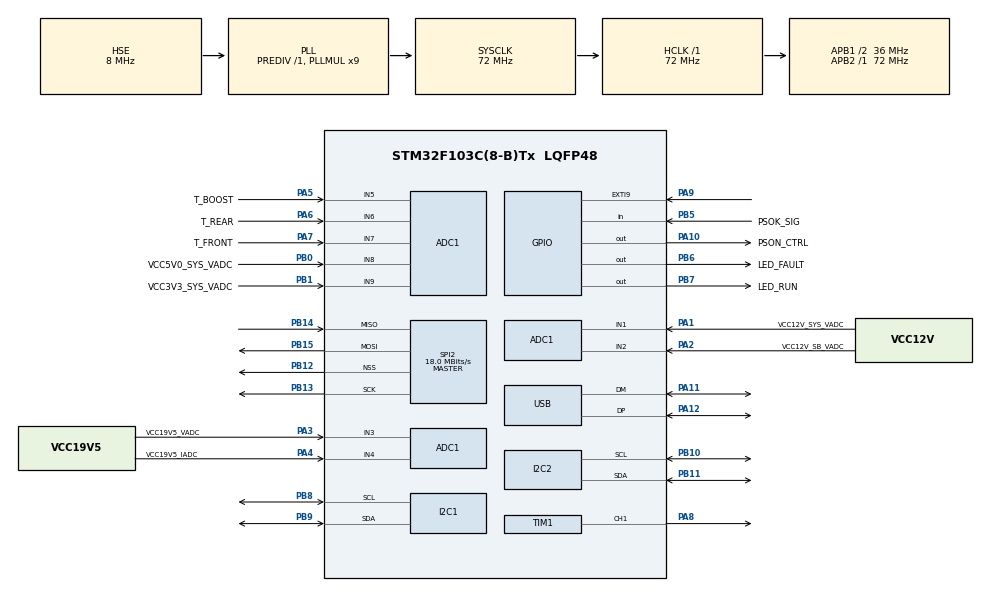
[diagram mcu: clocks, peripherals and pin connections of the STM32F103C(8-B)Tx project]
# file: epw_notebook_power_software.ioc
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ADC1.Channel-1\#ChannelRegularConversion=ADC_CHANNEL_1
ADC1.Channel-12\#ChannelRegularConversion=ADC_CHANNEL_2
ADC1.Channel-13\#ChannelRegularConversion=ADC_CHANNEL_3
ADC1.Channel-14\#ChannelRegularConversion=ADC_CHANNEL_4
ADC1.Channel-15\#ChannelRegularConversion=ADC_CHANNEL_5
ADC1.Channel-16\#ChannelRegularConversion=ADC_CHANNEL_6
ADC1.Channel-17\#ChannelRegularConversion=ADC_CHANNEL_7
ADC1.Channel-18\#ChannelRegularConversion=ADC_CHANNEL_8
ADC1.Channel-19\#ChannelRegularConversion=ADC_CHANNEL_9
ADC1.Channel-20\#ChannelRegularConversion=ADC_CHANNEL_TEMPSENSOR
ADC1.Channel-21\#ChannelRegularConversion=ADC_CHANNEL_VREFINT
ADC1.ContinuousConvMode=ENABLE
ADC1.NbrOfConversion=11
ADC1.NbrOfConversionFlag=1
ADC1.Rank-1\#ChannelRegularConversion=1
ADC1.Rank-12\#ChannelRegularConversion=2
ADC1.Rank-13\#ChannelRegularConversion=3
ADC1.Rank-14\#ChannelRegularConversion=4
ADC1.Rank-15\#ChannelRegularConversion=5
ADC1.Rank-16\#ChannelRegularConversion=6
ADC1.Rank-17\#ChannelRegularConversion=7
ADC1.Rank-18\#ChannelRegularConversion=8
ADC1.Rank-19\#ChannelRegularConversion=9
ADC1.Rank-20\#ChannelRegularConversion=10
ADC1.Rank-21\#ChannelRegularConversion=11
ADC1.SamplingTime-1\#ChannelRegularConversion=ADC_SAMPLETIME_1CYCLE_5
ADC1.SamplingTime-12\#ChannelRegularConversion=ADC_SAMPLETIME_1CYCLE_5
ADC1.SamplingTime-13\#ChannelRegularConversion=ADC_SAMPLETIME_1CYCLE_5
ADC1.SamplingTime-14\#ChannelRegularConversion=ADC_SAMPLETIME_1CYCLE_5
ADC1.SamplingTime-15\#ChannelRegularConversion=ADC_SAMPLETIME_1CYCLE_5
ADC1.SamplingTime-16\#ChannelRegularConversion=ADC_SAMPLETIME_1CYCLE_5
ADC1.SamplingTime-17\#ChannelRegularConversion=ADC_SAMPLETIME_1CYCLE_5
ADC1.SamplingTime-18\#ChannelRegularConversion=ADC_SAMPLETIME_1CYCLE_5
ADC1.SamplingTime-19\#ChannelRegularConversion=ADC_SAMPLETIME_1CYCLE_5
ADC1.SamplingTime-20\#ChannelRegularConversion=ADC_SAMPLETIME_1CYCLE_5
ADC1.SamplingTime-21\#ChannelRegularConversion=ADC_SAMPLETIME_1CYCLE_5
ADC1.master=1
Dma.ADC1.0.Direction=DMA_PERIPH_TO_MEMORY
Dma.ADC1.0.Instance=DMA1_Channel1
Dma.ADC1.0.MemDataAlignment=DMA_MDATAALIGN_HALFWORD
Dma.ADC1.0.MemInc=DMA_MINC_ENABLE
Dma.ADC1.0.Mode=DMA_CIRCULAR
Dma.ADC1.0.PeriphDataAlignment=DMA_PDATAALIGN_HALFWORD
Dma.ADC1.0.PeriphInc=DMA_PINC_DISABLE
Dma.ADC1.0.Priority=DMA_PRIORITY_LOW
Dma.Request0=ADC1
I2C2.I2C_Mode=I2C_Fast
I2C2.NoStretchMode=I2C_NOSTRETCH_DISABLE
I2C2.OwnAddress=0
Mcu.Family=STM32F1
Mcu.Name=STM32F103C(8-B)Tx
Mcu.Package=LQFP48
NVIC.DMA1_Channel1_IRQn=true\:0\:0\:false\:false\:true\:false\:true\:true
NVIC.EXTI9_5_IRQn=true\:0\:0\:false\:false\:true\:true\:true\:true
NVIC.PriorityGroup=NVIC_PRIORITYGROUP_4
NVIC.TIM2_IRQn=true\:0\:0\:false\:false\:true\:true\:true\:true
NVIC.USB_LP_CAN1_RX0_IRQn=true\:0\:0\:false\:false\:true\:false\:true\:true
PA1.GPIO_Label=VCC12V_SYS_VADC
PA1.Signal=ADCx_IN1
PA10.GPIO_Label=PSON_CTRL
PA10.GPIO_PuPd=GPIO_PULLDOWN
PA10.PinState=GPIO_PIN_RESET
PA10.Signal=GPIO_Output
PA11.Mode=Device
PA11.Signal=USB_DM
PA12.Mode=Device
PA12.Signal=USB_DP
PA13.Mode=Serial_Wire
PA13.Signal=SYS_JTMS-SWDIO
PA14.Mode=Serial_Wire
PA14.Signal=SYS_JTCK-SWCLK
PA2.GPIO_Label=VCC12V_SB_VADC
PA2.Signal=ADCx_IN2
PA3.GPIO_Label=VCC19V5_VADC
PA3.Signal=ADCx_IN3
PA4.GPIO_Label=VCC19V5_IADC
PA4.Signal=ADCx_IN4
PA5.GPIO_Label=T_BOOST
PA5.Signal=ADCx_IN5
PA6.GPIO_Label=T_REAR
PA6.Signal=ADCx_IN6
PA7.GPIO_Label=T_FRONT
PA7.Signal=ADCx_IN7
PA8.GPIO_ModeDefaultPP=GPIO_MODE_AF_PP
PA8.GPIO_Speed=GPIO_SPEED_FREQ_HIGH
PA8.Signal=S_TIM1_CH1
PA9.GPIO_ModeDefaultEXTI=GPIO_MODE_IT_RISING_FALLING
PA9.GPIO_PuPd=GPIO_PULLUP
PA9.Signal=GPXTI9
PB0.GPIO_Label=VCC5V0_SYS_VADC
PB0.Signal=ADCx_IN8
PB1.GPIO_Label=VCC3V3_SYS_VADC
PB1.Signal=ADCx_IN9
PB10.Mode=I2C
PB10.Signal=I2C2_SCL
PB11.Mode=I2C
PB11.Signal=I2C2_SDA
PB12.Mode=NSS_Signal_Hard_Output
PB12.Signal=SPI2_NSS
PB13.Mode=Full_Duplex_Master
PB13.Signal=SPI2_SCK
PB14.Mode=Full_Duplex_Master
PB14.Signal=SPI2_MISO
PB15.Mode=Full_Duplex_Master
PB15.Signal=SPI2_MOSI
PB5.GPIO_Label=PSOK_SIG
PB5.Signal=GPIO_Input
PB6.GPIO_Label=LED_FAULT
PB6.Signal=GPIO_Output
PB7.GPIO_Label=LED_RUN
PB7.PinState=GPIO_PIN_SET
PB7.Signal=GPIO_Output
PB8.Mode=I2C
PB8.Signal=I2C1_SCL
PB9.Mode=I2C
PB9.Signal=I2C1_SDA
PC14-OSC32_IN.Mode=LSE-External-Oscillator
PC14-OSC32_IN.Signal=RCC_OSC32_IN
PC15-OSC32_OUT.Mode=LSE-External-Oscillator
PC15-OSC32_OUT.Signal=RCC_OSC32_OUT
PD0-OSC_IN.Mode=HSE-External-Oscillator
PD0-OSC_IN.Signal=RCC_OSC_IN
PD1-OSC_OUT.Mode=HSE-External-Oscillator
PD1-OSC_OUT.Signal=RCC_OSC_OUT
ProjectManager.HeapSize=0x200
ProjectManager.StackSize=0x400
ProjectManager.TargetToolchain=STM32CubeIDE
RCC.ADCPresc=RCC_ADCPCLK2_DIV6
RCC.AHBFreq_Value=72000000
RCC.APB1CLKDivider=RCC_HCLK_DIV2
RCC.APB1Freq_Value=36000000
RCC.APB1TimFreq_Value=72000000
RCC.APB2Freq_Value=72000000
RCC.APB2TimFreq_Value=72000000
RCC.HCLKFreq_Value=72000000
RCC.PLLMUL=RCC_PLL_MUL9
RCC.SYSCLKFreq_VALUE=72000000
RCC.SYSCLKSource=RCC_SYSCLKSOURCE_PLLCLK
RCC.USBFreq_Value=48000000
RCC.USBPrescaler=RCC_USBCLKSOURCE_PLL_DIV1_5
SH.ADCx_IN1.0=ADC1_IN1,IN1
SH.ADCx_IN2.0=ADC1_IN2,IN2
SH.ADCx_IN3.0=ADC1_IN3,IN3
SH.ADCx_IN4.0=ADC1_IN4,IN4
SH.ADCx_IN5.0=ADC1_IN5,IN5
SH.ADCx_IN6.0=ADC1_IN6,IN6
SH.ADCx_IN7.0=ADC1_IN7,IN7
SH.ADCx_IN8.0=ADC1_IN8,IN8
SH.ADCx_IN9.0=ADC1_IN9,IN9
SH.S_TIM1_CH1.0=TIM1_CH1,PWM Generation1 CH1
SPI2.BaudRatePrescaler=SPI_BAUDRATEPRESCALER_2
SPI2.CalculateBaudRate=18.0 MBits/s
SPI2.Direction=SPI_DIRECTION_2LINES
SPI2.Mode=SPI_MODE_MASTER
SPI2.VirtualNSS=VM_NSSHARD
SPI2.VirtualType=VM_MASTER
TIM1.Channel-PWM\ Generation1\ CH1=TIM_CHANNEL_1
TIM1.OCMode_PWM-PWM\ Generation1\ CH1=TIM_OCMODE_PWM1
TIM1.Period=1439
TIM1.Prescaler=1
TIM2.AutoReloadPreload=TIM_AUTORELOAD_PRELOAD_DISABLE
TIM2.Period=10000-1
TIM2.Prescaler=7200-1
USB.low_power_enable=DISABLE
USB.lpm_enable=DISABLE
USB_DEVICE.CLASS_NAME_FS=CDC
USB_DEVICE.VirtualMode=Cdc
USB_DEVICE.VirtualModeFS=Cdc_FS
VP_ADC1_TempSens_Input.Mode=IN-TempSens
VP_ADC1_Vref_Input.Mode=IN-Vrefint
VP_IWDG_VS_IWDG.Mode=IWDG_Activate
VP_TIM1_VS_ClockSourceINT.Mode=Internal
VP_TIM2_VS_ClockSourceINT.Mode=Internal
VP_USB_DEVICE_VS_USB_DEVICE_CDC_FS.Mode=CDC_FS
board=custom

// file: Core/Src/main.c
/* USER CODE BEGIN Header */
/**
  ******************************************************************************
  * @file           : main.c
  * @brief          : Main program body
  ******************************************************************************
  * @attention
  *
  * Copyright (c) 2025 STMicroelectronics.
  * All rights reserved.
  *
  * This software is licensed under terms that can be found in the LICENSE file
  * in the root directory of this software component.
  * If no LICENSE file comes with this software, it is provided AS-IS.
  *
  ******************************************************************************
  */
/* USER CODE END Header */
#include "main.h"
#include "usb_device.h"

/* USER CODE BEGIN PD */
#define OLED_ADDRESS 0x78
#define OLED_DATA_ADDRESS 0x40
#define OLED_CMD_ADDRESS 0x00

#define PMBUS_EEPROM_ADDRESS 0xA0
#define PMBUS_MCU_ADDRESS 0xB0
/* USER CODE END PD */

ADC_HandleTypeDef hadc1;
DMA_HandleTypeDef hdma_adc1;

I2C_HandleTypeDef hi2c1;
I2C_HandleTypeDef hi2c2;

IWDG_HandleTypeDef hiwdg;

SPI_HandleTypeDef hspi2;

TIM_HandleTypeDef htim1;
TIM_HandleTypeDef htim2;

/* USER CODE BEGIN PV */
//8*6 ASCII字符集点阵
const unsigned char F6x8[][6] =
{
	0x00, 0x00, 0x00, 0x00, 0x00, 0x00,// sp
	0x00, 0x00, 0x00, 0x2f, 0x00, 0x00,// !
	0x00, 0x00, 0x07, 0x00, 0x07, 0x00,// "
	0x00, 0x14, 0x7f, 0x14, 0x7f, 0x14,// #
	0x00, 0x24, 0x2a, 0x7f, 0x2a, 0x12,// $
	0x00, 0x62, 0x64, 0x08, 0x13, 0x23,// %
	0x00, 0x36, 0x49, 0x55, 0x22, 0x50,// &
	0x00, 0x00, 0x05, 0x03, 0x00, 0x00,// '
	0x00, 0x00, 0x1c, 0x22, 0x41, 0x00,// (
	0x00, 0x00, 0x41, 0x22, 0x1c, 0x00,// )
	0x00, 0x14, 0x08, 0x3E, 0x08, 0x14,// *
	0x00, 0x08, 0x08, 0x3E, 0x08, 0x08,// +
	0x00, 0x00, 0x00, 0xA0, 0x60, 0x00,// ,
	0x00, 0x08, 0x08, 0x08, 0x08, 0x08,// -
	0x00, 0x00, 0x60, 0x60, 0x00, 0x00,// .
	0x00, 0x20, 0x10, 0x08, 0x04, 0x02,// /
	0x00, 0x3E, 0x51, 0x49, 0x45, 0x3E,// 0
	0x00, 0x00, 0x42, 0x7F, 0x40, 0x00,// 1
	0x00, 0x42, 0x61, 0x51, 0x49, 0x46,// 2
	0x00, 0x21, 0x41, 0x45, 0x4B, 0x31,// 3
	0x00, 0x18, 0x14, 0x12, 0x7F, 0x10,// 4
	0x00, 0x27, 0x45, 0x45, 0x45, 0x39,// 5
	0x00, 0x3C, 0x4A, 0x49, 0x49, 0x30,// 6
	0x00, 0x01, 0x71, 0x09, 0x05, 0x03,// 7
	0x00, 0x36, 0x49, 0x49, 0x49, 0x36,// 8
	0x00, 0x06, 0x49, 0x49, 0x29, 0x1E,// 9
	0x00, 0x00, 0x36, 0x36, 0x00, 0x00,// :
	0x00, 0x00, 0x56, 0x36, 0x00, 0x00,// ;
	0x00, 0x08, 0x14, 0x22, 0x41, 0x00,// <
	0x00, 0x14, 0x14, 0x14, 0x14, 0x14,// =
	0x00, 0x00, 0x41, 0x22, 0x14, 0x08,// >
	0x00, 0x02, 0x01, 0x51, 0x09, 0x06,// ?
	0x00, 0x32, 0x49, 0x59, 0x51, 0x3E,// @
	0x00, 0x7C, 0x12, 0x11, 0x12, 0x7C,// A
	0x00, 0x7F, 0x49, 0x49, 0x49, 0x36,// B
	0x00, 0x3E, 0x41, 0x41, 0x41, 0x22,// C
	0x00, 0x7F, 0x41, 0x41, 0x22, 0x1C,// D
	0x00, 0x7F, 0x49, 0x49, 0x49, 0x41,// E
	0x00, 0x7F, 0x09, 0x09, 0x09, 0x01,// F
	0x00, 0x3E, 0x41, 0x49, 0x49, 0x7A,// G
	0x00, 0x7F, 0x08, 0x08, 0x08, 0x7F,// H
	0x00, 0x00, 0x41, 0x7F, 0x41, 0x00,// I
	0x00, 0x20, 0x40, 0x41, 0x3F, 0x01,// J
	0x00, 0x7F, 0x08, 0x14, 0x22, 0x41,// K
	0x00, 0x7F, 0x40, 0x40, 0x40, 0x40,// L
	0x00, 0x7F, 0x02, 0x0C, 0x02, 0x7F,// M
	0x00, 0x7F, 0x04, 0x08, 0x10, 0x7F,// N
	0x00, 0x3E, 0x41, 0x41, 0x41, 0x3E,// O
	0x00, 0x7F, 0x09, 0x09, 0x09, 0x06,// P
	0x00, 0x3E, 0x41, 0x51, 0x21, 0x5E,// Q
	0x00, 0x7F, 0x09, 0x19, 0x29, 0x46,// R
	0x00, 0x46, 0x49, 0x49, 0x49, 0x31,// S
	0x00, 0x01, 0x01, 0x7F, 0x01, 0x01,// T
	0x00, 0x3F, 0x40, 0x40, 0x40, 0x3F,// U
	0x00, 0x1F, 0x20, 0x40, 0x20, 0x1F,// V
	0x00, 0x3F, 0x40, 0x38, 0x40, 0x3F,// W
	0x00, 0x63, 0x14, 0x08, 0x14, 0x63,// X
	0x00, 0x07, 0x08, 0x70, 0x08, 0x07,// Y
	0x00, 0x61, 0x51, 0x49, 0x45, 0x43,// Z
	0x00, 0x00, 0x7F, 0x41, 0x41, 0x00,// [
	0x00, 0x55, 0x2A, 0x55, 0x2A, 0x55,// 55
	0x00, 0x00, 0x41, 0x41, 0x7F, 0x00,// ]
	0x00, 0x04, 0x02, 0x01, 0x02, 0x04,// ^
	0x00, 0x40, 0x40, 0x40, 0x40, 0x40,// _
	0x00, 0x00, 0x01, 0x02, 0x04, 0x00,// '
	0x00, 0x20, 0x54, 0x54, 0x54, 0x78,// a
	0x00, 0x7F, 0x48, 0x44, 0x44, 0x38,// b
	0x00, 0x38, 0x44, 0x44, 0x44, 0x20,// c
	0x00, 0x38, 0x44, 0x44, 0x48, 0x7F,// d
	0x00, 0x38, 0x54, 0x54, 0x54, 0x18,// e
	0x00, 0x08, 0x7E, 0x09, 0x01, 0x02,// f
	0x00, 0x18, 0xA4, 0xA4, 0xA4, 0x7C,// g
	0x00, 0x7F, 0x08, 0x04, 0x04, 0x78,// h
	0x00, 0x00, 0x44, 0x7D, 0x40, 0x00,// i
	0x00, 0x40, 0x80, 0x84, 0x7D, 0x00,// j
	0x00, 0x7F, 0x10, 0x28, 0x44, 0x00,// k
	0x00, 0x00, 0x41, 0x7F, 0x40, 0x00,// l
	0x00, 0x7C, 0x04, 0x18, 0x04, 0x78,// m
	0x00, 0x7C, 0x08, 0x04, 0x04, 0x78,// n
	0x00, 0x38, 0x44, 0x44, 0x44, 0x38,// o
	0x00, 0xFC, 0x24, 0x24, 0x24, 0x18,// p
	0x00, 0x18, 0x24, 0x24, 0x18, 0xFC,// q
	0x00, 0x7C, 0x08, 0x04, 0x04, 0x08,// r
	0x00, 0x48, 0x54, 0x54, 0x54, 0x20,// s
	0x00, 0x04, 0x3F, 0x44, 0x40, 0x20,// t
	0x00, 0x3C, 0x40, 0x40, 0x20, 0x7C,// u
	0x00, 0x1C, 0x20, 0x40, 0x20, 0x1C,// v
	0x00, 0x3C, 0x40, 0x30, 0x40, 0x3C,// w
	0x00, 0x44, 0x28, 0x10, 0x28, 0x44,// x
	0x00, 0x1C, 0xA0, 0xA0, 0xA0, 0x7C,// y
	0x00, 0x44, 0x64, 0x54, 0x4C, 0x44,// z
	0x14, 0x14, 0x14, 0x14, 0x14, 0x14,// horiz lines
};

//16*8 ASCII字符集点阵
const unsigned char F8X16[]=
{
 0x00,0x00,0x00,0x00,0x00,0x00,0x00,0x00,0x00,0x00,0x00,0x00,0x00,0x00,0x00,0x00,//sp /0
 0x00,0x00,0x00,0xF8,0x00,0x00,0x00,0x00,0x00,0x00,0x00,0x33,0x30,0x00,0x00,0x00,//!  /1
 0x00,0x10,0x0C,0x06,0x10,0x0C,0x06,0x00,0x00,0x00,0x00,0x00,0x00,0x00,0x00,0x00,//"  /2
 0x40,0xC0,0x78,0x40,0xC0,0x78,0x40,0x00,0x04,0x3F,0x04,0x04,0x3F,0x04,0x04,0x00,//#  /3
 0x00,0x70,0x88,0xFC,0x08,0x30,0x00,0x00,0x00,0x18,0x20,0xFF,0x21,0x1E,0x00,0x00,//$  /4
 0xF0,0x08,0xF0,0x00,0xE0,0x18,0x00,0x00,0x00,0x21,0x1C,0x03,0x1E,0x21,0x1E,0x00,//%  /5
 0x00,0xF0,0x08,0x88,0x70,0x00,0x00,0x00,0x1E,0x21,0x23,0x24,0x19,0x27,0x21,0x10,//&  /6
 0x10,0x16,0x0E,0x00,0x00,0x00,0x00,0x00,0x00,0x00,0x00,0x00,0x00,0x00,0x00,0x00,//'  /7
 0x00,0x00,0x00,0xE0,0x18,0x04,0x02,0x00,0x00,0x00,0x00,0x07,0x18,0x20,0x40,0x00,//(  /8
 0x00,0x02,0x04,0x18,0xE0,0x00,0x00,0x00,0x00,0x40,0x20,0x18,0x07,0x00,0x00,0x00,//)  /9
 0x40,0x40,0x80,0xF0,0x80,0x40,0x40,0x00,0x02,0x02,0x01,0x0F,0x01,0x02,0x02,0x00,//*  /10
 0x00,0x00,0x00,0xF0,0x00,0x00,0x00,0x00,0x01,0x01,0x01,0x1F,0x01,0x01,0x01,0x00,//+  /11
 0x00,0x00,0x00,0x00,0x00,0x00,0x00,0x00,0x80,0xB0,0x70,0x00,0x00,0x00,0x00,0x00,//,  /12
 0x00,0x00,0x00,0x00,0x00,0x00,0x00,0x00,0x00,0x01,0x01,0x01,0x01,0x01,0x01,0x01,//-  /13
 0x00,0x00,0x00,0x00,0x00,0x00,0x00,0x00,0x00,0x30,0x30,0x00,0x00,0x00,0x00,0x00,//.  /14
 0x00,0x00,0x00,0x00,0x80,0x60,0x18,0x04,0x00,0x60,0x18,0x06,0x01,0x00,0x00,0x00,///  /15
 0x00,0xE0,0x10,0x08,0x08,0x10,0xE0,0x00,0x00,0x0F,0x10,0x20,0x20,0x10,0x0F,0x00,//0  /16
 0x00,0x10,0x10,0xF8,0x00,0x00,0x00,0x00,0x00,0x20,0x20,0x3F,0x20,0x20,0x00,0x00,//1  /17
 0x00,0x70,0x08,0x08,0x08,0x88,0x70,0x00,0x00,0x30,0x28,0x24,0x22,0x21,0x30,0x00,//2  /18
 0x00,0x30,0x08,0x88,0x88,0x48,0x30,0x00,0x00,0x18,0x20,0x20,0x20,0x11,0x0E,0x00,//3  /19
 0x00,0x00,0xC0,0x20,0x10,0xF8,0x00,0x00,0x00,0x07,0x04,0x24,0x24,0x3F,0x24,0x00,//4  /20
 0x00,0xF8,0x08,0x88,0x88,0x08,0x08,0x00,0x00,0x19,0x21,0x20,0x20,0x11,0x0E,0x00,//5  /21
 0x00,0xE0,0x10,0x88,0x88,0x18,0x00,0x00,0x00,0x0F,0x11,0x20,0x20,0x11,0x0E,0x00,//6  /22
 0x00,0x38,0x08,0x08,0xC8,0x38,0x08,0x00,0x00,0x00,0x00,0x3F,0x00,0x00,0x00,0x00,//7  /23
 0x00,0x70,0x88,0x08,0x08,0x88,0x70,0x00,0x00,0x1C,0x22,0x21,0x21,0x22,0x1C,0x00,//8  /24
 0x00,0xE0,0x10,0x08,0x08,0x10,0xE0,0x00,0x00,0x00,0x31,0x22,0x22,0x11,0x0F,0x00,//9  /25
 0x00,0x00,0x00,0xC0,0xC0,0x00,0x00,0x00,0x00,0x00,0x00,0x30,0x30,0x00,0x00,0x00,//:  /26
 0x00,0x00,0x00,0x80,0x00,0x00,0x00,0x00,0x00,0x00,0x80,0x60,0x00,0x00,0x00,0x00,//;  /27
 0x00,0x00,0x80,0x40,0x20,0x10,0x08,0x00,0x00,0x01,0x02,0x04,0x08,0x10,0x20,0x00,//<  /28
 0x40,0x40,0x40,0x40,0x40,0x40,0x40,0x00,0x04,0x04,0x04,0x04,0x04,0x04,0x04,0x00,//=  /29
 0x00,0x08,0x10,0x20,0x40,0x80,0x00,0x00,0x00,0x20,0x10,0x08,0x04,0x02,0x01,0x00,//>  /30
 0x00,0x70,0x48,0x08,0x08,0x08,0xF0,0x00,0x00,0x00,0x00,0x30,0x36,0x01,0x00,0x00,//?  /31
 0xC0,0x30,0xC8,0x28,0xE8,0x10,0xE0,0x00,0x07,0x18,0x27,0x24,0x23,0x14,0x0B,0x00,//@  /32
 0x00,0x00,0xC0,0x38,0xE0,0x00,0x00,0x00,0x20,0x3C,0x23,0x02,0x02,0x27,0x38,0x20,//A  /33
 0x08,0xF8,0x88,0x88,0x88,0x70,0x00,0x00,0x20,0x3F,0x20,0x20,0x20,0x11,0x0E,0x00,//B  /34
 0xC0,0x30,0x08,0x08,0x08,0x08,0x38,0x00,0x07,0x18,0x20,0x20,0x20,0x10,0x08,0x00,//C  /35
 0x08,0xF8,0x08,0x08,0x08,0x10,0xE0,0x00,0x20,0x3F,0x20,0x20,0x20,0x10,0x0F,0x00,//D  /36
 0x08,0xF8,0x88,0x88,0xE8,0x08,0x10,0x00,0x20,0x3F,0x20,0x20,0x23,0x20,0x18,0x00,//E  /37
 0x08,0xF8,0x88,0x88,0xE8,0x08,0x10,0x00,0x20,0x3F,0x20,0x00,0x03,0x00,0x00,0x00,//F  /38
 0xC0,0x30,0x08,0x08,0x08,0x38,0x00,0x00,0x07,0x18,0x20,0x20,0x22,0x1E,0x02,0x00,//G  /39
 0x08,0xF8,0x08,0x00,0x00,0x08,0xF8,0x08,0x20,0x3F,0x21,0x01,0x01,0x21,0x3F,0x20,//H  /40
 0x00,0x08,0x08,0xF8,0x08,0x08,0x00,0x00,0x00,0x20,0x20,0x3F,0x20,0x20,0x00,0x00,//I  /41
 0x00,0x00,0x08,0x08,0xF8,0x08,0x08,0x00,0xC0,0x80,0x80,0x80,0x7F,0x00,0x00,0x00,//J  /42
 0x08,0xF8,0x88,0xC0,0x28,0x18,0x08,0x00,0x20,0x3F,0x20,0x01,0x26,0x38,0x20,0x00,//K  /43
 0x08,0xF8,0x08,0x00,0x00,0x00,0x00,0x00,0x20,0x3F,0x20,0x20,0x20,0x20,0x30,0x00,//L  /44
 0x08,0xF8,0xF8,0x00,0xF8,0xF8,0x08,0x00,0x20,0x3F,0x00,0x3F,0x00,0x3F,0x20,0x00,//M  /45
 0x08,0xF8,0x30,0xC0,0x00,0x08,0xF8,0x08,0x20,0x3F,0x20,0x00,0x07,0x18,0x3F,0x00,//N  /46
 0xE0,0x10,0x08,0x08,0x08,0x10,0xE0,0x00,0x0F,0x10,0x20,0x20,0x20,0x10,0x0F,0x00,//O  /47
 0x08,0xF8,0x08,0x08,0x08,0x08,0xF0,0x00,0x20,0x3F,0x21,0x01,0x01,0x01,0x00,0x00,//P  /48
 0xE0,0x10,0x08,0x08,0x08,0x10,0xE0,0x00,0x0F,0x18,0x24,0x24,0x38,0x50,0x4F,0x00,//Q  /49
 0x08,0xF8,0x88,0x88,0x88,0x88,0x70,0x00,0x20,0x3F,0x20,0x00,0x03,0x0C,0x30,0x20,//R  /50
 0x00,0x70,0x88,0x08,0x08,0x08,0x38,0x00,0x00,0x38,0x20,0x21,0x21,0x22,0x1C,0x00,//S  /51
 0x18,0x08,0x08,0xF8,0x08,0x08,0x18,0x00,0x00,0x00,0x20,0x3F,0x20,0x00,0x00,0x00,//T  /52
 0x08,0xF8,0x08,0x00,0x00,0x08,0xF8,0x08,0x00,0x1F,0x20,0x20,0x20,0x20,0x1F,0x00,//U  /53
 0x08,0x78,0x88,0x00,0x00,0xC8,0x38,0x08,0x00,0x00,0x07,0x38,0x0E,0x01,0x00,0x00,//V  /54
 0xF8,0x08,0x00,0xF8,0x00,0x08,0xF8,0x00,0x03,0x3C,0x07,0x00,0x07,0x3C,0x03,0x00,//W  /55
 0x08,0x18,0x68,0x80,0x80,0x68,0x18,0x08,0x20,0x30,0x2C,0x03,0x03,0x2C,0x30,0x20,//X  /56
 0x08,0x38,0xC8,0x00,0xC8,0x38,0x08,0x00,0x00,0x00,0x20,0x3F,0x20,0x00,0x00,0x00,//Y  /57
 0x10,0x08,0x08,0x08,0xC8,0x38,0x08,0x00,0x20,0x38,0x26,0x21,0x20,0x20,0x18,0x00,//Z  /58
 0x00,0x00,0x00,0xFE,0x02,0x02,0x02,0x00,0x00,0x00,0x00,0x7F,0x40,0x40,0x40,0x00,//[  /59
 0x00,0x0C,0x30,0xC0,0x00,0x00,0x00,0x00,0x00,0x00,0x00,0x01,0x06,0x38,0xC0,0x00,//\  /60
 0x00,0x02,0x02,0x02,0xFE,0x00,0x00,0x00,0x00,0x40,0x40,0x40,0x7F,0x00,0x00,0x00,//]  /61
 0x00,0x00,0x04,0x02,0x02,0x02,0x04,0x00,0x00,0x00,0x00,0x00,0x00,0x00,0x00,0x00,//^  /62
 0x00,0x00,0x00,0x00,0x00,0x00,0x00,0x00,0x80,0x80,0x80,0x80,0x80,0x80,0x80,0x80,//_  /63
 0x00,0x02,0x02,0x04,0x00,0x00,0x00,0x00,0x00,0x00,0x00,0x00,0x00,0x00,0x00,0x00,//`  /64
 0x00,0x00,0x80,0x80,0x80,0x80,0x00,0x00,0x00,0x19,0x24,0x22,0x22,0x22,0x3F,0x20,//a  /65
 0x08,0xF8,0x00,0x80,0x80,0x00,0x00,0x00,0x00,0x3F,0x11,0x20,0x20,0x11,0x0E,0x00,//b  /66
 0x00,0x00,0x00,0x80,0x80,0x80,0x00,0x00,0x00,0x0E,0x11,0x20,0x20,0x20,0x11,0x00,//c  /67
 0x00,0x00,0x00,0x80,0x80,0x88,0xF8,0x00,0x00,0x0E,0x11,0x20,0x20,0x10,0x3F,0x20,//d  /68
 0x00,0x00,0x80,0x80,0x80,0x80,0x00,0x00,0x00,0x1F,0x22,0x22,0x22,0x22,0x13,0x00,//e  /69
 0x00,0x80,0x80,0xF0,0x88,0x88,0x88,0x18,0x00,0x20,0x20,0x3F,0x20,0x20,0x00,0x00,//f  /70
 0x00,0x00,0x80,0x80,0x80,0x80,0x80,0x00,0x00,0x6B,0x94,0x94,0x94,0x93,0x60,0x00,//g  /71
 0x08,0xF8,0x00,0x80,0x80,0x80,0x00,0x00,0x20,0x3F,0x21,0x00,0x00,0x20,0x3F,0x20,//h  /72
 0x00,0x80,0x98,0x98,0x00,0x00,0x00,0x00,0x00,0x20,0x20,0x3F,0x20,0x20,0x00,0x00,//i  /73
 0x00,0x00,0x00,0x80,0x98,0x98,0x00,0x00,0x00,0xC0,0x80,0x80,0x80,0x7F,0x00,0x00,//j  /74
 0x08,0xF8,0x00,0x00,0x80,0x80,0x80,0x00,0x20,0x3F,0x24,0x02,0x2D,0x30,0x20,0x00,//k  /75
 0x00,0x08,0x08,0xF8,0x00,0x00,0x00,0x00,0x00,0x20,0x20,0x3F,0x20,0x20,0x00,0x00,//l  /76
 0x80,0x80,0x80,0x80,0x80,0x80,0x80,0x00,0x20,0x3F,0x20,0x00,0x3F,0x20,0x00,0x3F,//m  /77
 0x80,0x80,0x00,0x80,0x80,0x80,0x00,0x00,0x20,0x3F,0x21,0x00,0x00,0x20,0x3F,0x20,//n  /78
 0x00,0x00,0x80,0x80,0x80,0x80,0x00,0x00,0x00,0x1F,0x20,0x20,0x20,0x20,0x1F,0x00,//o  /79
 0x80,0x80,0x00,0x80,0x80,0x00,0x00,0x00,0x80,0xFF,0xA1,0x20,0x20,0x11,0x0E,0x00,//p  /80
 0x00,0x00,0x00,0x80,0x80,0x80,0x80,0x00,0x00,0x0E,0x11,0x20,0x20,0xA0,0xFF,0x80,//q  /81
 0x80,0x80,0x80,0x00,0x80,0x80,0x80,0x00,0x20,0x20,0x3F,0x21,0x20,0x00,0x01,0x00,//r  /82
 0x00,0x00,0x80,0x80,0x80,0x80,0x80,0x00,0x00,0x33,0x24,0x24,0x24,0x24,0x19,0x00,//s  /83
 0x00,0x80,0x80,0xE0,0x80,0x80,0x00,0x00,0x00,0x00,0x00,0x1F,0x20,0x20,0x00,0x00,//t  /84
 0x80,0x80,0x00,0x00,0x00,0x80,0x80,0x00,0x00,0x1F,0x20,0x20,0x20,0x10,0x3F,0x20,//u  /85
 0x80,0x80,0x80,0x00,0x00,0x80,0x80,0x80,0x00,0x01,0x0E,0x30,0x08,0x06,0x01,0x00,//v  /86
 0x80,0x80,0x00,0x80,0x00,0x80,0x80,0x80,0x0F,0x30,0x0C,0x03,0x0C,0x30,0x0F,0x00,//w  /87
 0x00,0x80,0x80,0x00,0x80,0x80,0x80,0x00,0x00,0x20,0x31,0x2E,0x0E,0x31,0x20,0x00,//x  /88
 0x80,0x80,0x80,0x00,0x00,0x80,0x80,0x80,0x80,0x81,0x8E,0x70,0x18,0x06,0x01,0x00,//y  /89
 0x00,0x80,0x80,0x80,0x80,0x80,0x80,0x00,0x00,0x21,0x30,0x2C,0x22,0x21,0x30,0x00,//z  /90
 0x00,0x00,0x00,0x00,0x80,0x7C,0x02,0x02,0x00,0x00,0x00,0x00,0x00,0x3F,0x40,0x40,//{  /91
 0x00,0x02,0x02,0x7C,0x80,0x00,0x00,0x00,0x00,0x40,0x40,0x3F,0x00,0x00,0x00,0x00,//}  /92
 0x00,0x00,0x00,0x00,0xFF,0x00,0x00,0x00,0x00,0x00,0x00,0x00,0xFF,0x00,0x00,0x00};//|  /93

const unsigned char OLED_BMP_SYS[] =
{
		0xFF,0x01,0x01,0x11,0xF1,0x1D,0x11,0x11,0xC1,0xA1,0xB1,0xA9,0x2D,0x31,0x21,0x21,
		0x01,0x01,0x01,0xF9,0x81,0x81,0x81,0xF1,0x81,0x81,0x81,0x81,0xF9,0x01,0x01,0x01,
		0x03,0x05,0x09,0x11,0x21,0x41,0x81,0x01,0x01,0x01,0x01,0x01,0x01,0x01,0x01,0x01,
		0x01,0x01,0x01,0x01,0x11,0x11,0x11,0xE1,0x01,0x01,0x01,0x11,0x11,0x11,0xE1,0x01,
		0x01,0xC1,0x31,0x11,0x11,0x31,0xC1,0x01,0x01,0x01,0x01,0x01,0x01,0x31,0xC1,0x01,
		0x01,0x01,0x01,0xE1,0x11,0x01,0x01,0x01,0x01,0x01,0x01,0x01,0x01,0x01,0x01,0x01,
		0x01,0xC1,0x31,0x11,0x11,0x31,0xC1,0x01,0xC1,0x31,0x11,0x11,0x31,0xC1,0x01,0x01,
		0x01,0x01,0x01,0x01,0x01,0x01,0x81,0x61,0x71,0x81,0x01,0x01,0x01,0x01,0x01,0xFF,
		0xFF,0x00,0x00,0x00,0x13,0x12,0x7F,0x12,0xFF,0x14,0x94,0xFF,0x00,0xBF,0x80,0xFF,
		0x00,0x00,0x7C,0x40,0x40,0x40,0x40,0x7F,0x40,0x40,0x40,0x40,0x40,0x7C,0x00,0x00,
		0x00,0x00,0x00,0x00,0x00,0x00,0x00,0x01,0x02,0x04,0x08,0x10,0x20,0x40,0x80,0x00,
		0x00,0x00,0x00,0x18,0x14,0x12,0x11,0x10,0x00,0x00,0x18,0x14,0x12,0x11,0x10,0x00,
		0x00,0x07,0x18,0x10,0x10,0x18,0x07,0x00,0x00,0x00,0x00,0x00,0x00,0x00,0x00,0x07,
		0x18,0x0C,0x03,0x00,0x00,0x00,0x00,0x00,0x00,0x00,0x00,0x00,0x00,0x00,0x00,0x00,
		0x00,0x07,0x18,0x10,0x10,0x18,0x07,0x00,0x07,0x18,0x10,0x10,0x18,0x07,0x00,0x00,
		0x00,0x00,0x00,0x00,0x10,0x0E,0x05,0x04,0x04,0x05,0x0E,0x10,0x00,0x00,0x00,0xFF,
		0xFF,0x00,0x00,0x00,0x80,0x60,0x20,0x20,0x60,0x80,0x00,0x00,0x00,0x80,0x60,0x20,
		0x20,0x60,0x80,0x00,0x80,0x60,0x20,0x20,0x60,0x80,0x00,0x00,0x00,0x00,0x00,0x00,
		0x00,0x60,0x80,0x00,0x00,0x00,0x00,0xC0,0x20,0x00,0x00,0x00,0x00,0x00,0x00,0x01,
		0x02,0xFC,0x04,0x04,0x04,0x44,0x44,0xC4,0x44,0x44,0xC4,0x04,0x04,0x04,0x04,0x04,
		0x04,0x04,0x04,0x04,0x04,0x04,0x04,0x04,0x04,0x04,0x04,0x04,0x04,0x04,0x04,0x04,
		0x04,0x04,0x04,0x04,0x04,0x04,0x04,0x04,0x04,0x04,0x04,0x84,0xC4,0x44,0xC4,0x84,
		0x84,0xC4,0x44,0xC4,0x84,0x04,0x04,0x04,0x04,0xC4,0x44,0xC4,0x04,0x84,0x44,0x44,
		0x44,0x04,0x04,0x04,0x04,0x04,0x04,0x04,0x04,0x04,0x04,0x04,0x04,0x04,0x04,0xFF,
		0xFF,0x00,0x00,0x00,0x0F,0x30,0x20,0x20,0x30,0x0F,0x20,0x00,0x00,0x0F,0x30,0x20,
		0x20,0x30,0x0F,0x00,0x0F,0x30,0x20,0x20,0x30,0x0F,0x00,0x00,0x00,0x00,0x00,0x00,
		0x00,0x00,0x01,0x0E,0x30,0x18,0x06,0x01,0x00,0x00,0x00,0x00,0x00,0x00,0x00,0x00,
		0x00,0xFF,0x00,0x00,0x00,0x00,0x00,0x3F,0x00,0x00,0x3F,0x02,0x02,0x02,0x3E,0x00,
		0x00,0x00,0x00,0x00,0x00,0x00,0x00,0x00,0x00,0x00,0x00,0x00,0x00,0x00,0x00,0x00,
		0x00,0x00,0x00,0x00,0x00,0x00,0x00,0x00,0x00,0x00,0x00,0x1F,0x30,0x20,0x30,0x1F,
		0x1F,0x30,0x20,0x30,0x1F,0x00,0x00,0x00,0x00,0x01,0x01,0x01,0x0F,0x10,0x20,0x20,
		0x20,0x00,0x00,0x00,0x00,0x00,0x00,0x00,0x00,0x00,0x00,0x00,0x00,0x00,0x00,0xFF,
		0xFF,0x00,0x00,0x00,0xE0,0x18,0x08,0x08,0x18,0xE0,0x00,0x00,0x00,0xE0,0x18,0x08,
		0x08,0x18,0xE0,0x00,0xE0,0x18,0x08,0x08,0x18,0xE0,0x00,0x00,0x00,0x00,0x00,0x00,
		0x00,0x00,0x00,0xC0,0x30,0x38,0xC0,0x00,0x00,0x00,0x00,0x00,0x00,0x00,0x00,0x00,
		0x00,0xFF,0x00,0x00,0x00,0xFC,0x44,0x44,0x00,0xE0,0x98,0x98,0xE0,0x00,0x00,0xFC,
		0x08,0x30,0xC0,0x00,0xFC,0x00,0x00,0x00,0x00,0x00,0x00,0x00,0x00,0x00,0x00,0x00,
		0xF8,0x0C,0x04,0x0C,0xF8,0x00,0xF8,0x0C,0x04,0x0C,0xF8,0xF8,0x0C,0x04,0x0C,0xF8,
		0x00,0xF8,0x0C,0x04,0x0C,0xF8,0x00,0x00,0x00,0xFC,0x44,0x44,0xC4,0x38,0x00,0xFC,
		0x44,0x44,0x44,0x38,0x00,0xFC,0x18,0xE0,0x00,0x80,0x60,0x18,0xFC,0x00,0x00,0xFF,
		0xFF,0x00,0x00,0x00,0x03,0x0C,0x08,0x08,0x0C,0x03,0x08,0x00,0x00,0x03,0x0C,0x08,
		0x08,0x0C,0x03,0x00,0x03,0x0C,0x08,0x08,0x0C,0x03,0x00,0x00,0x00,0x00,0x00,0x00,
		0x00,0x08,0x07,0x02,0x02,0x02,0x02,0x07,0x08,0x00,0x00,0x00,0x00,0x00,0x00,0x00,
		0x00,0xFF,0x80,0x80,0x80,0x83,0x80,0x80,0x83,0x80,0x80,0x80,0x80,0x83,0x80,0x83,
		0x80,0x80,0x80,0x81,0x83,0x80,0x80,0x80,0x80,0x80,0x80,0x80,0x80,0x80,0x80,0x80,
		0x81,0x83,0x82,0x83,0x81,0x80,0x81,0x83,0x82,0x83,0x81,0x81,0x83,0x82,0x83,0x81,
		0x80,0x81,0x83,0x82,0x83,0x81,0x80,0x80,0x80,0x83,0x80,0x80,0x81,0x82,0x80,0x83,
		0x80,0x80,0x80,0x80,0x80,0x83,0x80,0x80,0x81,0x81,0x80,0x80,0x83,0x80,0x80,0xFF,
		0xFF,0x00,0x00,0x00,0xF0,0x0C,0x04,0x04,0x0C,0xF0,0x00,0x00,0x00,0xF0,0x0C,0x04,
		0x04,0x0C,0xF0,0x00,0xF0,0x0C,0x04,0x04,0x0C,0xF0,0x00,0x00,0x00,0x00,0x00,0x00,
		0x00,0x0C,0x70,0x80,0x00,0xC0,0x38,0x18,0xE0,0x00,0x80,0x70,0x0C,0x00,0x00,0x00,
		0x00,0xFF,0x00,0x00,0x00,0x00,0x00,0x00,0xC0,0x30,0x38,0xC0,0x00,0x00,0x00,0x00,
		0xC0,0x30,0x38,0xC0,0x00,0x00,0x00,0x00,0xC0,0x30,0x38,0xC0,0x00,0x00,0x00,0x00,
		0x00,0x00,0x00,0x00,0x00,0x00,0x00,0x00,0x00,0x00,0x00,0x00,0x00,0x00,0x00,0x00,
		0x00,0x00,0x00,0x00,0x00,0x00,0x00,0x00,0x00,0x00,0x00,0x00,0x00,0x00,0x00,0x00,
		0x00,0x00,0x00,0x00,0x00,0x00,0x00,0x00,0x00,0x00,0x00,0x00,0x00,0x00,0x00,0xFF,
		0xFF,0x80,0x80,0x80,0x81,0x86,0x84,0x84,0x86,0x81,0x84,0x80,0x80,0x81,0x86,0x84,
		0x84,0x86,0x81,0x80,0x81,0x86,0x84,0x84,0x86,0x81,0x80,0x80,0x80,0x80,0x80,0x80,
		0x80,0x80,0x80,0x83,0x86,0x81,0x80,0x80,0x80,0x87,0x83,0x80,0x80,0x80,0x80,0x80,
		0x80,0xFF,0x80,0x80,0x80,0x80,0x88,0x87,0x82,0x82,0x82,0x82,0x87,0x88,0x88,0x87,
		0x82,0x82,0x82,0x82,0x87,0x88,0x88,0x87,0x82,0x82,0x82,0x82,0x87,0x88,0x80,0x80,
		0x80,0x80,0x80,0x80,0x80,0x80,0x80,0x80,0x80,0x80,0x80,0x80,0x80,0x80,0x80,0x80,
		0x80,0x80,0x80,0x80,0x80,0x80,0x80,0x80,0x80,0x80,0x80,0x80,0x80,0x80,0x80,0x80,
		0x80,0x80,0x80,0x80,0x80,0x80,0x80,0x80,0x80,0x80,0x80,0x80,0x80,0x80,0x80,0xFF
};

const unsigned char OLED_BMP_INIT[] =
{
		0xFF,0x01,0x01,0x01,0x01,0x01,0x01,0x01,0x01,0x01,0x01,0x01,0x01,0x01,0x01,0x01,
		0x01,0x01,0x01,0x01,0x01,0x01,0x01,0x01,0x01,0x01,0x01,0x01,0x01,0x01,0x01,0x01,
		0x01,0x01,0x01,0x01,0x01,0x01,0x01,0x01,0x01,0x01,0x01,0x01,0x01,0x01,0x01,0x01,
		0x01,0x01,0x01,0x01,0x01,0x01,0x01,0x01,0x01,0x01,0x01,0x01,0x01,0x01,0x01,0x01,
		0x01,0x01,0x01,0x01,0x01,0x01,0x01,0x01,0x01,0x01,0x01,0x01,0x01,0x01,0x01,0x01,
		0x01,0x01,0x01,0x01,0x01,0x01,0x01,0x01,0x01,0x01,0x01,0x01,0x01,0x01,0x01,0x01,
		0x01,0x01,0x01,0x01,0x01,0x01,0x01,0x01,0x01,0x01,0x01,0x01,0x01,0x01,0x01,0x01,
		0x01,0x01,0x01,0x01,0x01,0x01,0x01,0x01,0x01,0x01,0x01,0x01,0x01,0x01,0x01,0xFF,
		0xFF,0x00,0x00,0x00,0x00,0x00,0x00,0x00,0x00,0x00,0x00,0x00,0x00,0x00,0x00,0x00,
		0x00,0x00,0x00,0x00,0x00,0x00,0x00,0x00,0x00,0x00,0x00,0x00,0x00,0x00,0x00,0x00,
		0x00,0x00,0x00,0x00,0x00,0x00,0x00,0x00,0x00,0x00,0x00,0x00,0x00,0x00,0x00,0x00,
		0x00,0x00,0x00,0x00,0x00,0x00,0x00,0x00,0x00,0x00,0x00,0x00,0x00,0x00,0x00,0x00,
		0x00,0x00,0x00,0x00,0x00,0x00,0x00,0x00,0x00,0x00,0x00,0x00,0x00,0x00,0x00,0x00,
		0x00,0x00,0x00,0x00,0x00,0x00,0x00,0x00,0x00,0x00,0x00,0x00,0x00,0x00,0x00,0x00,
		0x00,0x00,0x00,0x00,0x00,0x00,0x00,0x00,0x00,0x00,0x00,0x00,0x00,0x00,0x00,0x00,
		0x00,0x00,0x00,0x00,0x00,0x00,0x00,0x00,0x00,0x00,0x00,0x00,0x00,0x00,0x00,0xFF,
		0xFF,0x00,0x00,0x00,0x00,0x00,0x00,0x80,0x40,0x40,0x40,0x40,0x40,0x00,0x00,0x00,
		0x40,0x80,0x00,0x00,0x00,0x00,0x00,0x00,0x00,0xC0,0x40,0x00,0x00,0x00,0x80,0x40,
		0x40,0x40,0x40,0x40,0x00,0x00,0x40,0x40,0x40,0x40,0x40,0xC0,0x40,0x40,0x40,0x40,
		0x40,0x00,0x00,0x00,0xC0,0x40,0x40,0x40,0x40,0x40,0x40,0x40,0x00,0x00,0x00,0xC0,
		0x80,0x00,0x00,0x00,0x00,0x00,0x00,0x00,0x00,0x00,0x00,0x00,0x80,0xC0,0x00,0x00,
		0x00,0x00,0x00,0x00,0x00,0x00,0x00,0x00,0xC0,0x00,0x00,0x00,0x00,0xC0,0x80,0x00,
		0x00,0x00,0x00,0x00,0x00,0x00,0x00,0x00,0xC0,0x00,0x00,0x00,0x00,0xC0,0x00,0x00,
		0x00,0x40,0x40,0x40,0x40,0x40,0xC0,0x40,0x40,0x40,0x40,0x40,0x00,0x00,0x00,0xFF,
		0xFF,0x00,0x00,0x00,0x00,0x00,0x0F,0x10,0x30,0x20,0x40,0xC0,0x80,0x00,0x00,0x00,
		0x00,0x03,0x0C,0x70,0x80,0x60,0x18,0x0C,0x03,0x00,0x00,0x00,0x00,0x0F,0x10,0x30,
		0x20,0x40,0xC0,0x80,0x00,0x00,0x00,0x00,0x00,0x00,0x00,0xFF,0x00,0x00,0x00,0x00,
		0x00,0x00,0x00,0x00,0xFF,0x20,0x20,0x20,0x20,0x20,0x20,0x00,0x00,0x00,0x00,0xFF,
		0x03,0x0E,0x38,0xC0,0x00,0x00,0x00,0x00,0x00,0xC0,0x30,0x0E,0x03,0xFF,0x00,0x00,
		0x00,0x00,0x00,0x00,0x00,0x00,0x00,0x00,0xFF,0x00,0x00,0x00,0x00,0xFF,0x01,0x03,
		0x04,0x18,0x30,0xC0,0x80,0x00,0x00,0x00,0xFF,0x00,0x00,0x00,0x00,0xFF,0x00,0x00,
		0x00,0x00,0x00,0x00,0x00,0x00,0xFF,0x00,0x00,0x00,0x00,0x00,0x00,0x00,0x00,0xFF,
		0xFF,0x00,0x00,0x00,0x00,0x00,0x10,0x20,0x20,0x20,0x20,0x20,0x10,0x0F,0x00,0x00,
		0x00,0x00,0x00,0x00,0x3F,0x00,0x00,0x00,0x00,0x00,0x00,0x00,0x00,0x10,0x20,0x20,
		0x20,0x20,0x20,0x10,0x0F,0x00,0x00,0x00,0x00,0x00,0x00,0x3F,0x00,0x00,0x00,0x00,
		0x00,0x00,0x00,0x00,0x3F,0x20,0x20,0x20,0x20,0x20,0x20,0x20,0x00,0x00,0x00,0x3F,
		0x00,0x00,0x00,0x00,0x03,0x0C,0x30,0x0C,0x03,0x00,0x00,0x00,0x00,0x3F,0x00,0x00,
		0x00,0x00,0x00,0x00,0x00,0x00,0x00,0x00,0x3F,0x00,0x00,0x00,0x00,0x3F,0x00,0x00,
		0x00,0x00,0x00,0x00,0x01,0x03,0x0C,0x18,0x3F,0x00,0x00,0x00,0x00,0x3F,0x00,0x00,
		0x00,0x00,0x00,0x00,0x00,0x00,0x3F,0x00,0x00,0x00,0x00,0x00,0x00,0x00,0x00,0xFF,
		0xFF,0x00,0x00,0x00,0x00,0x00,0x00,0x00,0x00,0x00,0x00,0x00,0x00,0x00,0x00,0x00,
		0x00,0x00,0x00,0x00,0x00,0x00,0x00,0x00,0x00,0x00,0x00,0x00,0x00,0x00,0x00,0x00,
		0x00,0x00,0x00,0x00,0x00,0x00,0x00,0x00,0x00,0x00,0x00,0x00,0x00,0x00,0x00,0x00,
		0x00,0x00,0x00,0x00,0x00,0x00,0x00,0x00,0x00,0x00,0x00,0x00,0x00,0x00,0x00,0x00,
		0x00,0x00,0x00,0x00,0x00,0x00,0x00,0x00,0x00,0x00,0x00,0x00,0x00,0x00,0x00,0x00,
		0x00,0x00,0x00,0x00,0x00,0x00,0x00,0x00,0x00,0x00,0x00,0x00,0x00,0x00,0x00,0x00,
		0x00,0x00,0x00,0x00,0x00,0x00,0x00,0x00,0x00,0x00,0x00,0x00,0x00,0x00,0x00,0x00,
		0x00,0x00,0x00,0x00,0x00,0x00,0x00,0x00,0x00,0x00,0x00,0x00,0x00,0x00,0x00,0xFF,
		0xFF,0x00,0x00,0x00,0x00,0x00,0x00,0x00,0x00,0x00,0x00,0x00,0x00,0x00,0x00,0x00,
		0x00,0x00,0x00,0x00,0x00,0x00,0x00,0x00,0x00,0x00,0x00,0x00,0x00,0x00,0x00,0x00,
		0x00,0x00,0x00,0x00,0x00,0x00,0x00,0x00,0x00,0x00,0x00,0x00,0x00,0x00,0x00,0x00,
		0x00,0x00,0x00,0x00,0x00,0x00,0x00,0x00,0x00,0x00,0x00,0x00,0x00,0x00,0x00,0x00,
		0x00,0x00,0x00,0x00,0x00,0x00,0x00,0x00,0x00,0x00,0x00,0x00,0x00,0x00,0x00,0x00,
		0x00,0x00,0x00,0x00,0x00,0x00,0x00,0x00,0x00,0x00,0x00,0x00,0x00,0x00,0x00,0x00,
		0x00,0x00,0x00,0x00,0x00,0x00,0x00,0x00,0x00,0x00,0x00,0x00,0x00,0x00,0x00,0x00,
		0x00,0x00,0x00,0x00,0x00,0x00,0x00,0x00,0x00,0x00,0x00,0x00,0x00,0x00,0x00,0xFF,
		0xFF,0x80,0x80,0x80,0x80,0x80,0x80,0x80,0x80,0x80,0x80,0x80,0x80,0x80,0x80,0x80,
		0x80,0x80,0x80,0x80,0x80,0x80,0x80,0x80,0x80,0x80,0x80,0x80,0x80,0x80,0x80,0x80,
		0x80,0x80,0x80,0x80,0x80,0x80,0x80,0x80,0x80,0x80,0x80,0x80,0x80,0x80,0x80,0x80,
		0x80,0x80,0x80,0x80,0x80,0x80,0x80,0x80,0x80,0x80,0x80,0x80,0x80,0x80,0x80,0x80,
		0x80,0x80,0x80,0x80,0x80,0x80,0x80,0x80,0x80,0x80,0x80,0x80,0x80,0x80,0x80,0x80,
		0x80,0x80,0x80,0x80,0x80,0x80,0x80,0x80,0x80,0x80,0x80,0x80,0x80,0x80,0x80,0x80,
		0x80,0x80,0x80,0x80,0x80,0x80,0x80,0x80,0x80,0x80,0x80,0x80,0x80,0x80,0x80,0x80,
		0x80,0x80,0x80,0x80,0x80,0x80,0x80,0x80,0x80,0x80,0x80,0x80,0x80,0x80,0x80,0xFF
};

static uint8_t SYS_Power_State = 0;

static uint8_t PMBUS_Recv_Buf_PSMI_0x04[2] = {};
static uint8_t PMBUS_Recv_Buf_PSMI_0x1A[1] = {};
static uint8_t PMBUS_Recv_Buf_PSMI_0x98[1] = {};
static uint8_t PMBUS_Recv_Buf_PSMI_0x0E[1] = {};
static uint8_t PMBUS_Recv_Buf_PSMI_0x10[1] = {};
static uint8_t PMBUS_Recv_Buf_PSMI_0x08[1] = {};
static uint8_t PMBUS_Recv_Buf_PSMI_0x0C[1] = {};
static uint8_t PMBUS_Recv_Buf_PSMI_0x12[1] = {};
static uint8_t PMBUS_Recv_Buf_PSMI_0x1E[1] = {};
static uint8_t PMBUS_Recv_Buf_PSMI_0x00[2] = {};
static uint8_t PMBUS_Recv_Buf_PSMI_0x02[2] = {};
static uint8_t PMBUS_Recv_Buf_FRU[255] = {};

uint16_t ADC_Value[11] = {0};
float VCC19V5_VADC = 0, VCC19V5_IADC = 0, Output_19V5_Power = 0;
float VCC12V_SYS_VADC = 0, VCC12V_SB_VADC = 0, VCC5V0_SYS_VADC = 0, VCC3V3_SYS_VADC = 0;
float T_BOOST = 0, T_REAR = 0, T_FRONT = 0;
float T_IN = 0, Vref_IN = 0;

uint32_t SYS_FAN_TACH_Count = 0;
uint32_t SYS_FAN_Speed = 0;
/* USER CODE END PV */

void SystemClock_Config(void);
static void MX_GPIO_Init(void);
static void MX_DMA_Init(void);
static void MX_ADC1_Init(void);
static void MX_I2C1_Init(void);
static void MX_I2C2_Init(void);
static void MX_TIM1_Init(void);
static void MX_SPI2_Init(void);
static void MX_TIM2_Init(void);
static void MX_IWDG_Init(void);
/* USER CODE BEGIN PFP */
void Feed_IWDG(void)
{
	HAL_IWDG_Refresh(&hiwdg);
}
void OLED_Write_Command(uint8_t oled_wr_data)
{
	HAL_I2C_Mem_Write(&hi2c2, OLED_ADDRESS, OLED_CMD_ADDRESS, 1, &oled_wr_data, 1, 10);
}

void OLED_Write_Data(uint8_t oled_wr_data)
{
	HAL_I2C_Mem_Write(&hi2c2, OLED_ADDRESS, OLED_DATA_ADDRESS, 1, &oled_wr_data, 1, 10);
}

void OLED_Clear(void) // 清屏
{
	uint8_t i, j;
	for(i = 0; i < 8; i++)
	{
		OLED_Write_Command(0xB0 + i);
		OLED_Write_Command(0x00);
		OLED_Write_Command(0x10);
		for(j = 0; j < 128; j++)
		{
			OLED_Write_Data(0x00);
		}
	}
}

void Start_OLED(void)
{
	OLED_Write_Command(0xAE);
	OLED_Write_Command(0x00);
	OLED_Write_Command(0x10);
	OLED_Write_Command(0x40);
	OLED_Write_Command(0x81);
	OLED_Write_Command(0xCF);
	OLED_Write_Command(0xA1);
	OLED_Write_Command(0xC8);
	OLED_Write_Command(0xA6);
	OLED_Write_Command(0xA8);
	OLED_Write_Command(0x3F);
	OLED_Write_Command(0xD3);
	OLED_Write_Command(0x00);
	OLED_Write_Command(0xD5);
	OLED_Write_Command(0x80);
	OLED_Write_Command(0xD9);
	OLED_Write_Command(0xF1);
	OLED_Write_Command(0xDA);
	OLED_Write_Command(0x12);
	OLED_Write_Command(0xDB);
	OLED_Write_Command(0x30);
	OLED_Write_Command(0x20);
	OLED_Write_Command(0x02);
	OLED_Write_Command(0x8D);
	OLED_Write_Command(0x14);
	OLED_Write_Command(0xAF);
}

void OLED_Set_Position(uint8_t pos_x, uint8_t pos_y)
{
	OLED_Write_Command(0xB0 + pos_y); // 设置页地址(0-7)
	OLED_Write_Command(((pos_x & 0xF0) >> 4) | 0x10); // 设置列高地址Display Position
	OLED_Write_Command(pos_x & 0x0F); // 设置列低地址Display Position
}

void OLED_Display_On(void) // OLED开显示
{
	OLED_Write_Command(0x8D);
	OLED_Write_Command(0x14);
	OLED_Write_Command(0xAF);
}

void OLED_Display_Off(void) // OLED关显示
{
	OLED_Write_Command(0x8D);
	OLED_Write_Command(0x10);
	OLED_Write_Command(0xAE);
}

void OLED_Fill_Color(void) // OLED亮屏(写0xFF)
{
	uint8_t i, j;
	for(i = 0; i < 8; i++)
	{
		OLED_Write_Command(0xB0 + i);
		OLED_Write_Command(0x00);
		OLED_Write_Command(0x10);
		for(j = 0; j < 128; j++)
		{
			OLED_Write_Data(0xFF);
		}
	}
}

void OLED_Show_Char(uint8_t x, uint8_t y, uint8_t chr, uint8_t size, uint8_t color_turn)
{
	unsigned char c = 0, i = 0;
	c = chr - ' '; // 得到偏移后的值
	if(x > 128 - 1)
	{
		x = 0;
		y = y + 2;
	}
	if(size == 16)
	{
		OLED_Set_Position(x, y);
		for(i = 0; i < 8; i++)
		{
			if(color_turn)
			{
				OLED_Write_Data(~F8X16[c * 16 + i]);
			}
			else
			{
				OLED_Write_Data(F8X16[c * 16 + i]);
			}
		}
		OLED_Set_Position(x, y + 1);
		for(i = 0; i < 8; i++)
		{
			if(color_turn)
			{
				OLED_Write_Data(~F8X16[c * 16 + i + 8]);
			}
			else
			{
				OLED_Write_Data(F8X16[c * 16 + i + 8]);
			}

		}

	}
	else
	{
		OLED_Set_Position(x, y);
		for(i = 0; i < 6; i++)
		{
			if(color_turn)
			{
				OLED_Write_Data(~F6x8[c][i]);
			}
			else
			{
				OLED_Write_Data(F6x8[c][i]);
			}
		}
	}
}

void OLED_Show_String(uint8_t x, uint8_t y, char* chr, uint8_t size, uint8_t color_turn)
{
	uint8_t j = 0;

	while(chr[j] != '\0')
	{
		OLED_Show_Char(x, y, chr[j], size, color_turn);
		if(size == 12)
		{
			x += 6;
		}
		else
		{
			x += 8;
		}
		if(x > 122 && size == 12)
		{
			x = 0;
			y++;
		}
		if(x > 120 && size == 16)
		{
			x = 0;
			y++;
		}
		j++;
	}
}

unsigned int OLED_POW(uint8_t m, uint8_t n)
{
	unsigned int result = 1;
	while(n--)result *= m;
	return result;
}

void OLED_Show_Num(uint8_t x, uint8_t y, unsigned int num, uint8_t len, uint8_t size2, uint8_t color_turn)
{
	uint8_t t, temp;
	uint8_t enshow = 0;
	for(t = 0; t < len; t++)
	{
		temp = (num / OLED_POW(10, len - t - 1)) % 10;
		if(enshow == 0 && t < (len - 1))
		{
			if(temp == 0)
			{
				OLED_Show_Char(x + (size2 / 2) * t, y, ' ', size2, color_turn);
				continue;
			}
			else
			{
				enshow = 1;
			}
		}
	 	OLED_Show_Char(x + (size2 / 2) * t, y, temp + '0', size2, color_turn);
	}
}

void OLED_Show_Decimal(uint8_t x, uint8_t y, float num, uint8_t z_len, uint8_t f_len, uint8_t size2, uint8_t color_turn)
{
	uint8_t t, temp, i = 0;//i为负数标志位
	uint8_t enshow;
	int z_temp, f_temp;
	if(num < 0)
	{
		z_len += 1;
		i = 1;
		num =- num;
	}
	z_temp = (int)num;
	//整数部分
	for(t = 0; t < z_len; t++)
	{
		temp = (z_temp / OLED_POW(10, z_len - t - 1)) % 10;
		if(enshow == 0 && t < (z_len - 1))
		{
			if(temp == 0)
			{
				OLED_Show_Char(x + (size2 / 2) * t, y, ' ', size2, color_turn);
				continue;
			}
			else
			enshow=1;
		}
		OLED_Show_Char(x + (size2 / 2) * t, y, temp + '0', size2, color_turn);
	}
	//小数点
	OLED_Show_Char(x + (size2 / 2) * (z_len), y, '.', size2, color_turn);

	f_temp = (int)((num-z_temp) * (OLED_POW(10, f_len)));
  //小数部分
	for(t = 0; t < f_len; t++)
	{
		temp = (f_temp / OLED_POW(10, f_len - t - 1)) % 10;
		OLED_Show_Char(x + (size2 / 2) * (t + z_len) + 5, y, temp + '0', size2, color_turn);
	}
	if(i == 1)//如果为负，就将最前的一位赋值‘-’
	{
		OLED_Show_Char(x, y, '-', size2, color_turn);
		i = 0;
	}
}

void OLED_Show_BMP(uint8_t bmp)
{
	uint8_t i = 0;
	uint32_t j = 0, j1 = 0;

	if(bmp)
	{
		for(i = 0; i < 8; i++)
		{
			OLED_Set_Position(0, i);
			for(j = 0; j < 128; j++)
			{
				OLED_Write_Data(OLED_BMP_SYS[j1++]);
			}
		}
	}
	else
	{
		for(i = 0; i < 8; i++)
		{
			OLED_Set_Position(0, i);
			for(j = 0; j < 128; j++)
			{
				OLED_Write_Data(OLED_BMP_INIT[j1++]);
			}
		}
	}
}

void OLED_Show_StartMenu(void)
{
	OLED_Show_String(0, 0, "Output", 16, 0);
	OLED_Show_Decimal(0, 2, VCC19V5_VADC, 4, 1, 16, 0);
	OLED_Show_String(48, 2, "V", 16, 0);
	OLED_Show_Decimal(0, 4, VCC19V5_IADC, 4, 1, 16, 0);
	OLED_Show_String(48, 4, "A", 16, 0);
	OLED_Show_Decimal(0, 6, Output_19V5_Power, 4, 1, 16, 0);
	OLED_Show_String(48, 6, "W", 16, 0);

	OLED_Show_String(64, 0, "Vin", 12, 0);
	// OLED_Show_Decimal(90, 0, (float*)PMBUS_Recv_Buf_PSMI_0x08, 4, 1, 12, 0);

	OLED_Show_String(64, 1, "Fan", 12, 0);
	OLED_Show_Num(95, 1, SYS_FAN_Speed, 5, 12, 0);

	OLED_Show_String(64, 2, "T1", 12, 0);
	OLED_Show_Decimal(90, 2, T_FRONT, 4, 1, 12, 0);

	OLED_Show_String(64, 3, "T2", 12, 0);
	OLED_Show_Decimal(90, 3, T_REAR, 4, 1, 12, 0);

	OLED_Show_String(64, 4, "T3", 12, 0);
	OLED_Show_Decimal(90, 4, T_BOOST, 4, 1, 12, 0);

	OLED_Show_String(64, 5, "T4", 12, 0);
	OLED_Show_Decimal(90, 5, T_IN, 4, 1, 12, 0);

	OLED_Show_String(64, 6, "Vref", 12, 0);
	OLED_Show_Decimal(90, 6, Vref_IN, 4, 1, 12, 0);

	OLED_Show_String(64, 7, "PSON  ", 12, 1);
	OLED_Show_Num(95, 7, SYS_Power_State, 5, 12, 1);
}

void PS_Power_Control(uint8_t state) // PSON控制
{
	if(state)
	{
		HAL_GPIO_WritePin(PSON_CTRL_GPIO_Port, PSON_CTRL_Pin, GPIO_PIN_SET);
		SYS_Power_State = 1;
	}
	else
	{
		HAL_GPIO_WritePin(PSON_CTRL_GPIO_Port, PSON_CTRL_Pin, GPIO_PIN_RESET);
		SYS_Power_State = 0;
	}
}

void PMBUS_Read_PSMI(void)
{
	HAL_I2C_Mem_Read(&hi2c1, PMBUS_MCU_ADDRESS, 0x04, 2, PMBUS_Recv_Buf_PSMI_0x04, 1, 10);
	HAL_I2C_Mem_Read(&hi2c1, PMBUS_MCU_ADDRESS, 0x1A, 1, PMBUS_Recv_Buf_PSMI_0x1A, 1, 10);
	HAL_I2C_Mem_Read(&hi2c1, PMBUS_MCU_ADDRESS, 0x98, 1, PMBUS_Recv_Buf_PSMI_0x98, 1, 10);
	HAL_I2C_Mem_Read(&hi2c1, PMBUS_MCU_ADDRESS, 0x0E, 1, PMBUS_Recv_Buf_PSMI_0x0E, 1, 10);
	HAL_I2C_Mem_Read(&hi2c1, PMBUS_MCU_ADDRESS, 0x10, 1, PMBUS_Recv_Buf_PSMI_0x10, 1, 10);
	HAL_I2C_Mem_Read(&hi2c1, PMBUS_MCU_ADDRESS, 0x08, 1, PMBUS_Recv_Buf_PSMI_0x08, 1, 10);
	HAL_I2C_Mem_Read(&hi2c1, PMBUS_MCU_ADDRESS, 0x0C, 1, PMBUS_Recv_Buf_PSMI_0x0C, 1, 10);
	HAL_I2C_Mem_Read(&hi2c1, PMBUS_MCU_ADDRESS, 0x12, 1, PMBUS_Recv_Buf_PSMI_0x12, 1, 10);
	HAL_I2C_Mem_Read(&hi2c1, PMBUS_MCU_ADDRESS, 0x1E, 1, PMBUS_Recv_Buf_PSMI_0x1E, 1, 10);
	HAL_I2C_Mem_Read(&hi2c1, PMBUS_MCU_ADDRESS, 0x00, 2, PMBUS_Recv_Buf_PSMI_0x00, 1, 10);
	HAL_I2C_Mem_Read(&hi2c1, PMBUS_MCU_ADDRESS, 0x02, 2, PMBUS_Recv_Buf_PSMI_0x02, 1, 10);
}

void PMBUS_Read_FRU(void)
{
	HAL_I2C_Mem_Read(&hi2c1, PMBUS_EEPROM_ADDRESS, 0xA1, 255, PMBUS_Recv_Buf_FRU, 1, 10);
}

void USB_CDC_Transmit_PMBUS_PSMI(void)
{
	CDC_Transmit_FS("\n", 1);
	HAL_Delay(1);

	CDC_Transmit_FS("PMBUS_PSMI", 10);
	HAL_Delay(1);
	CDC_Transmit_FS("\n", 1);
	HAL_Delay(1);

	CDC_Transmit_FS("0x04", 4);
	HAL_Delay(1);
	CDC_Transmit_FS("\n", 1);
	HAL_Delay(1);
	CDC_Transmit_FS(PMBUS_Recv_Buf_PSMI_0x04, 2);
	HAL_Delay(1);
	CDC_Transmit_FS("\n", 1);
	HAL_Delay(1);

	CDC_Transmit_FS("0x1A", 4);
	HAL_Delay(1);
	CDC_Transmit_FS("\n", 1);
	HAL_Delay(1);
	CDC_Transmit_FS(PMBUS_Recv_Buf_PSMI_0x1A, 1);
	HAL_Delay(1);
	CDC_Transmit_FS("\n", 1);
	HAL_Delay(1);

	CDC_Transmit_FS("0x98", 4);
	HAL_Delay(1);
	CDC_Transmit_FS("\n", 1);
	HAL_Delay(1);
	CDC_Transmit_FS(PMBUS_Recv_Buf_PSMI_0x98, 1);
	HAL_Delay(1);
	CDC_Transmit_FS("\n", 1);
	HAL_Delay(1);

	CDC_Transmit_FS("0x0E", 4);
	HAL_Delay(1);
	CDC_Transmit_FS("\n", 1);
	HAL_Delay(1);
	CDC_Transmit_FS(PMBUS_Recv_Buf_PSMI_0x0E, 1);
	HAL_Delay(1);
	CDC_Transmit_FS("\n", 1);
	HAL_Delay(1);

	CDC_Transmit_FS("0x10", 4);
	HAL_Delay(1);
	CDC_Transmit_FS("\n", 1);
	HAL_Delay(1);
	CDC_Transmit_FS(PMBUS_Recv_Buf_PSMI_0x10, 1);
	HAL_Delay(1);
	CDC_Transmit_FS("\n", 1);
	HAL_Delay(1);

	CDC_Transmit_FS("0x08", 4);
	HAL_Delay(1);
	CDC_Transmit_FS("\n", 1);
	HAL_Delay(1);
	CDC_Transmit_FS(PMBUS_Recv_Buf_PSMI_0x08, 1);
	HAL_Delay(1);
	CDC_Transmit_FS("\n", 1);
	HAL_Delay(1);

	CDC_Transmit_FS("0x0C", 4);
	HAL_Delay(1);
	CDC_Transmit_FS("\n", 1);
	HAL_Delay(1);
	CDC_Transmit_FS(PMBUS_Recv_Buf_PSMI_0x0C, 1);
	HAL_Delay(1);
	CDC_Transmit_FS("\n", 1);
	HAL_Delay(1);

	CDC_Transmit_FS("0x12", 4);
	HAL_Delay(1);
	CDC_Transmit_FS("\n", 1);
	HAL_Delay(1);
	CDC_Transmit_FS(PMBUS_Recv_Buf_PSMI_0x12, 1);
	HAL_Delay(1);
	CDC_Transmit_FS("\n", 1);
	HAL_Delay(1);

	CDC_Transmit_FS("0x1E", 4);
	HAL_Delay(1);
	CDC_Transmit_FS("\n", 1);
	HAL_Delay(1);
	CDC_Transmit_FS(PMBUS_Recv_Buf_PSMI_0x1E, 1);
	HAL_Delay(1);
	CDC_Transmit_FS("\n", 1);
	HAL_Delay(1);

	CDC_Transmit_FS("0x00", 4);
	HAL_Delay(1);
	CDC_Transmit_FS("\n", 1);
	HAL_Delay(1);
	CDC_Transmit_FS(PMBUS_Recv_Buf_PSMI_0x00, 2);
	HAL_Delay(1);
	CDC_Transmit_FS("\n", 1);
	HAL_Delay(1);

	CDC_Transmit_FS("0x02", 4);
	HAL_Delay(1);
	CDC_Transmit_FS("\n", 1);
	HAL_Delay(1);
	CDC_Transmit_FS(PMBUS_Recv_Buf_PSMI_0x02, 2);
	HAL_Delay(1);
	CDC_Transmit_FS("\n", 1);
	HAL_Delay(1);
}

void USB_CDC_Transmit_PMBUS_FRU(void)
{
	CDC_Transmit_FS("\n", 1);
	HAL_Delay(1);

	CDC_Transmit_FS("PMBUS_FRU", 9);
	HAL_Delay(1);
	CDC_Transmit_FS("\n", 1);
	HAL_Delay(1);

	CDC_Transmit_FS(PMBUS_Recv_Buf_PSMI_0x02, 255);
	HAL_Delay(1);
	CDC_Transmit_FS("\n", 1);
	HAL_Delay(1);
}

void USB_CDC_Transmit_SYS_Status(void)
{
	USB_CDC_Transmit_PMBUS_PSMI();
}

/*
 * SYS_LED_Control
 *
 * 0 = 关闭
 * 1 = 闪烁(1000ms)
 * 2 = 闪烁(500ms)
 * 3 = 常亮
 *
 * 注意：关闭是GPIO_PIN_SET, 打开是GPIO_PIN_RESET
 */
void SYS_LED_Control_Run(uint8_t state)
{
	if(state == 1)
	{
		HAL_GPIO_TogglePin(LED_RUN_GPIO_Port, LED_RUN_Pin);
		HAL_Delay(1000);
	}
	else if(state == 2)
	{
		HAL_GPIO_TogglePin(LED_RUN_GPIO_Port, LED_RUN_Pin);
		HAL_Delay(500);
	}
	else if(state == 3)
	{
		HAL_GPIO_WritePin(LED_RUN_GPIO_Port, LED_RUN_Pin, GPIO_PIN_RESET);
	}
	else
	{
		HAL_GPIO_WritePin(LED_RUN_GPIO_Port, LED_RUN_Pin, GPIO_PIN_SET);
	}
}

void SYS_LED_Control_Fault(uint8_t state)
{
	if(state == 1)
	{
		HAL_GPIO_TogglePin(LED_FAULT_GPIO_Port, LED_FAULT_Pin);
		HAL_Delay(1000);
	}
	else if(state == 2)
	{
		HAL_GPIO_TogglePin(LED_FAULT_GPIO_Port, LED_FAULT_Pin);
		HAL_Delay(500);
	}
	else if(state == 3)
	{
		HAL_GPIO_WritePin(LED_FAULT_GPIO_Port, LED_FAULT_Pin, GPIO_PIN_RESET);
	}
	else
	{
		HAL_GPIO_WritePin(LED_FAULT_GPIO_Port, LED_FAULT_Pin, GPIO_PIN_SET);
	}
}

void SYS_ADC_Convert_Value(void)
{
	VCC12V_SYS_VADC = (float)ADC_Value[0] * Vref_IN / 4096;
	VCC12V_SB_VADC = (float)ADC_Value[1] * Vref_IN / 4096;
	VCC19V5_VADC = (float)ADC_Value[2] * Vref_IN / 4096;
	VCC19V5_IADC = (float)ADC_Value[3] * Vref_IN / 4096;
	T_BOOST = (float)ADC_Value[4] * Vref_IN / 4096;
	T_REAR = (float)ADC_Value[5] * Vref_IN / 4096;
	T_FRONT = (float)ADC_Value[6] * Vref_IN / 4096;
	VCC5V0_SYS_VADC = (float)ADC_Value[7] * Vref_IN / 4096;
	VCC3V3_SYS_VADC = (float)ADC_Value[8] * Vref_IN / 4096;
	T_IN = (float)ADC_Value[9] * Vref_IN / 4096;
	Vref_IN = (float)ADC_Value[10] * 3.3f / 4096;
}

/*
 * 风扇速度控制
 * 风扇速度0-100, 0是最低速度(不一定会停转，看风扇)
 * ARR为1400, 所以这里输入的速度要 * 14.4
 */
void SYS_FAN_Control(uint8_t speed)
{
	uint32_t pwm_speed = 0;
	pwm_speed = speed * 14.4;

	__HAL_TIM_SET_COMPARE(&htim1, TIM_CHANNEL_1, pwm_speed);
}
/* USER CODE END PFP */

int main(void)
{

  /* MCU Configuration--------------------------------------------------------*/

  /* Reset of all peripherals, Initializes the Flash interface and the Systick. */
  HAL_Init();

  /* Configure the system clock */
  SystemClock_Config();

  /* Initialize all configured peripherals */
  MX_GPIO_Init();
  MX_DMA_Init();
  MX_ADC1_Init();
  MX_I2C1_Init();
  MX_I2C2_Init();
  MX_TIM1_Init();
  MX_USB_DEVICE_Init();
  MX_SPI2_Init();
  MX_TIM2_Init();

  /* USER CODE BEGIN 2 */
  HAL_Delay(500);

  SYS_LED_Control_Fault(3);

  HAL_TIM_PWM_Start(&htim1, TIM_CHANNEL_1);

  HAL_ADCEx_Calibration_Start(&hadc1);
  HAL_Delay(10);
  ADC_Enable(&hadc1);
  HAL_ADC_Start_DMA(&hadc1, (uint32_t*)ADC_Value, 11);

  SYS_FAN_Control(100);

  Start_OLED();
  OLED_Clear();
  OLED_Set_Position(0, 0);
  OLED_Show_BMP(0);

  PMBUS_Read_FRU();

  HAL_Delay(500);

  OLED_Clear();
  SYS_FAN_Control(0);

  HAL_TIM_Base_Start_IT(&htim2);

  HAL_Delay(5000);
  PS_Power_Control(1);
  SYS_LED_Control_Fault(0);
  SYS_LED_Control_Run(1);

  /*
   * 如果用MX重新生成过代码的话，需要在这里初始化IWDG
   */
  MX_IWDG_Init();

  /* USER CODE END 2 */

  /* Infinite loop */
  /* USER CODE BEGIN WHILE */
  while (1)
  {
	  Feed_IWDG();
	  OLED_Show_StartMenu();
    /* USER CODE END WHILE */

  }
}

void SystemClock_Config(void)
{
  RCC_OscInitTypeDef RCC_OscInitStruct = {0};
  RCC_ClkInitTypeDef RCC_ClkInitStruct = {0};
  RCC_PeriphCLKInitTypeDef PeriphClkInit = {0};

  /** Initializes the RCC Oscillators according to the specified parameters
  * in the RCC_OscInitTypeDef structure.
  */
  RCC_OscInitStruct.OscillatorType = RCC_OSCILLATORTYPE_LSI|RCC_OSCILLATORTYPE_HSE;
  RCC_OscInitStruct.HSEState = RCC_HSE_ON;
  RCC_OscInitStruct.HSEPredivValue = RCC_HSE_PREDIV_DIV1;
  RCC_OscInitStruct.HSIState = RCC_HSI_ON;
  RCC_OscInitStruct.LSIState = RCC_LSI_ON;
  RCC_OscInitStruct.PLL.PLLState = RCC_PLL_ON;
  RCC_OscInitStruct.PLL.PLLSource = RCC_PLLSOURCE_HSE;
  RCC_OscInitStruct.PLL.PLLMUL = RCC_PLL_MUL9;
  if (HAL_RCC_OscConfig(&RCC_OscInitStruct) != HAL_OK)
  {
    Error_Handler();
  }

  /** Initializes the CPU, AHB and APB buses clocks
  */
  RCC_ClkInitStruct.ClockType = RCC_CLOCKTYPE_HCLK|RCC_CLOCKTYPE_SYSCLK
                              |RCC_CLOCKTYPE_PCLK1|RCC_CLOCKTYPE_PCLK2;
  RCC_ClkInitStruct.SYSCLKSource = RCC_SYSCLKSOURCE_PLLCLK;
  RCC_ClkInitStruct.AHBCLKDivider = RCC_SYSCLK_DIV1;
  RCC_ClkInitStruct.APB1CLKDivider = RCC_HCLK_DIV2;
  RCC_ClkInitStruct.APB2CLKDivider = RCC_HCLK_DIV1;

  if (HAL_RCC_ClockConfig(&RCC_ClkInitStruct, FLASH_LATENCY_2) != HAL_OK)
  {
    Error_Handler();
  }
  PeriphClkInit.PeriphClockSelection = RCC_PERIPHCLK_ADC|RCC_PERIPHCLK_USB;
  PeriphClkInit.AdcClockSelection = RCC_ADCPCLK2_DIV6;
  PeriphClkInit.UsbClockSelection = RCC_USBCLKSOURCE_PLL_DIV1_5;
  if (HAL_RCCEx_PeriphCLKConfig(&PeriphClkInit) != HAL_OK)
  {
    Error_Handler();
  }
}

static void MX_ADC1_Init(void)
{

  ADC_ChannelConfTypeDef sConfig = {0};

  /** Common config
  */
  hadc1.Instance = ADC1;
  hadc1.Init.ScanConvMode = ADC_SCAN_ENABLE;
  hadc1.Init.ContinuousConvMode = ENABLE;
  hadc1.Init.DiscontinuousConvMode = DISABLE;
  hadc1.Init.ExternalTrigConv = ADC_SOFTWARE_START;
  hadc1.Init.DataAlign = ADC_DATAALIGN_RIGHT;
  hadc1.Init.NbrOfConversion = 11;
  if (HAL_ADC_Init(&hadc1) != HAL_OK)
  {
    Error_Handler();
  }

  /** Configure Regular Channel
  */
  sConfig.Channel = ADC_CHANNEL_1;
  sConfig.Rank = ADC_REGULAR_RANK_1;
  sConfig.SamplingTime = ADC_SAMPLETIME_1CYCLE_5;
  if (HAL_ADC_ConfigChannel(&hadc1, &sConfig) != HAL_OK)
  {
    Error_Handler();
  }

  /** Configure Regular Channel
  */
  sConfig.Channel = ADC_CHANNEL_2;
  sConfig.Rank = ADC_REGULAR_RANK_2;
  if (HAL_ADC_ConfigChannel(&hadc1, &sConfig) != HAL_OK)
  {
    Error_Handler();
  }

  /** Configure Regular Channel
  */
  sConfig.Channel = ADC_CHANNEL_3;
  sConfig.Rank = ADC_REGULAR_RANK_3;
  if (HAL_ADC_ConfigChannel(&hadc1, &sConfig) != HAL_OK)
  {
    Error_Handler();
  }

  /** Configure Regular Channel
  */
  sConfig.Channel = ADC_CHANNEL_4;
  sConfig.Rank = ADC_REGULAR_RANK_4;
  if (HAL_ADC_ConfigChannel(&hadc1, &sConfig) != HAL_OK)
  {
    Error_Handler();
  }

  /** Configure Regular Channel
  */
  sConfig.Channel = ADC_CHANNEL_5;
  sConfig.Rank = ADC_REGULAR_RANK_5;
  if (HAL_ADC_ConfigChannel(&hadc1, &sConfig) != HAL_OK)
  {
    Error_Handler();
  }

  /** Configure Regular Channel
  */
  sConfig.Channel = ADC_CHANNEL_6;
  sConfig.Rank = ADC_REGULAR_RANK_6;
  if (HAL_ADC_ConfigChannel(&hadc1, &sConfig) != HAL_OK)
  {
    Error_Handler();
  }

  /** Configure Regular Channel
  */
  sConfig.Channel = ADC_CHANNEL_7;
  sConfig.Rank = ADC_REGULAR_RANK_7;
  if (HAL_ADC_ConfigChannel(&hadc1, &sConfig) != HAL_OK)
  {
    Error_Handler();
  }

  /** Configure Regular Channel
  */
  sConfig.Channel = ADC_CHANNEL_8;
  sConfig.Rank = ADC_REGULAR_RANK_8;
  if (HAL_ADC_ConfigChannel(&hadc1, &sConfig) != HAL_OK)
  {
    Error_Handler();
  }

  /** Configure Regular Channel
  */
  sConfig.Channel = ADC_CHANNEL_9;
  sConfig.Rank = ADC_REGULAR_RANK_9;
  if (HAL_ADC_ConfigChannel(&hadc1, &sConfig) != HAL_OK)
  {
    Error_Handler();
  }

  /** Configure Regular Channel
  */
  sConfig.Channel = ADC_CHANNEL_TEMPSENSOR;
  sConfig.Rank = ADC_REGULAR_RANK_10;
  if (HAL_ADC_ConfigChannel(&hadc1, &sConfig) != HAL_OK)
  {
    Error_Handler();
  }

  /** Configure Regular Channel
  */
  sConfig.Channel = ADC_CHANNEL_VREFINT;
  sConfig.Rank = ADC_REGULAR_RANK_11;
  if (HAL_ADC_ConfigChannel(&hadc1, &sConfig) != HAL_OK)
  {
    Error_Handler();
  }

}

static void MX_I2C1_Init(void)
{

  hi2c1.Instance = I2C1;
  hi2c1.Init.ClockSpeed = 100000;
  hi2c1.Init.DutyCycle = I2C_DUTYCYCLE_2;
  hi2c1.Init.OwnAddress1 = 0;
  hi2c1.Init.AddressingMode = I2C_ADDRESSINGMODE_7BIT;
  hi2c1.Init.DualAddressMode = I2C_DUALADDRESS_DISABLE;
  hi2c1.Init.OwnAddress2 = 0;
  hi2c1.Init.GeneralCallMode = I2C_GENERALCALL_DISABLE;
  hi2c1.Init.NoStretchMode = I2C_NOSTRETCH_DISABLE;
  if (HAL_I2C_Init(&hi2c1) != HAL_OK)
  {
    Error_Handler();
  }

}

static void MX_I2C2_Init(void)
{

  hi2c2.Instance = I2C2;
  hi2c2.Init.ClockSpeed = 400000;
  hi2c2.Init.DutyCycle = I2C_DUTYCYCLE_2;
  hi2c2.Init.OwnAddress1 = 0;
  hi2c2.Init.AddressingMode = I2C_ADDRESSINGMODE_7BIT;
  hi2c2.Init.DualAddressMode = I2C_DUALADDRESS_DISABLE;
  hi2c2.Init.OwnAddress2 = 0;
  hi2c2.Init.GeneralCallMode = I2C_GENERALCALL_DISABLE;
  hi2c2.Init.NoStretchMode = I2C_NOSTRETCH_DISABLE;
  if (HAL_I2C_Init(&hi2c2) != HAL_OK)
  {
    Error_Handler();
  }

}

static void MX_IWDG_Init(void)
{

  hiwdg.Instance = IWDG;
  hiwdg.Init.Prescaler = IWDG_PRESCALER_4;
  hiwdg.Init.Reload = 4095;
  if (HAL_IWDG_Init(&hiwdg) != HAL_OK)
  {
    Error_Handler();
  }

}

static void MX_SPI2_Init(void)
{

  /* SPI2 parameter configuration*/
  hspi2.Instance = SPI2;
  hspi2.Init.Mode = SPI_MODE_MASTER;
  hspi2.Init.Direction = SPI_DIRECTION_2LINES;
  hspi2.Init.DataSize = SPI_DATASIZE_8BIT;
  hspi2.Init.CLKPolarity = SPI_POLARITY_LOW;
  hspi2.Init.CLKPhase = SPI_PHASE_1EDGE;
  hspi2.Init.NSS = SPI_NSS_HARD_OUTPUT;
  hspi2.Init.BaudRatePrescaler = SPI_BAUDRATEPRESCALER_2;
  hspi2.Init.FirstBit = SPI_FIRSTBIT_MSB;
  hspi2.Init.TIMode = SPI_TIMODE_DISABLE;
  hspi2.Init.CRCCalculation = SPI_CRCCALCULATION_DISABLE;
  hspi2.Init.CRCPolynomial = 10;
  if (HAL_SPI_Init(&hspi2) != HAL_OK)
  {
    Error_Handler();
  }

}

static void MX_TIM1_Init(void)
{

  TIM_ClockConfigTypeDef sClockSourceConfig = {0};
  TIM_MasterConfigTypeDef sMasterConfig = {0};
  TIM_OC_InitTypeDef sConfigOC = {0};
  TIM_BreakDeadTimeConfigTypeDef sBreakDeadTimeConfig = {0};

  htim1.Instance = TIM1;
  htim1.Init.Prescaler = 1;
  htim1.Init.CounterMode = TIM_COUNTERMODE_UP;
  htim1.Init.Period = 1439;
  htim1.Init.ClockDivision = TIM_CLOCKDIVISION_DIV1;
  htim1.Init.RepetitionCounter = 0;
  htim1.Init.AutoReloadPreload = TIM_AUTORELOAD_PRELOAD_DISABLE;
  if (HAL_TIM_Base_Init(&htim1) != HAL_OK)
  {
    Error_Handler();
  }
  sClockSourceConfig.ClockSource = TIM_CLOCKSOURCE_INTERNAL;
  if (HAL_TIM_ConfigClockSource(&htim1, &sClockSourceConfig) != HAL_OK)
  {
    Error_Handler();
  }
  if (HAL_TIM_PWM_Init(&htim1) != HAL_OK)
  {
    Error_Handler();
  }
  sMasterConfig.MasterOutputTrigger = TIM_TRGO_RESET;
  sMasterConfig.MasterSlaveMode = TIM_MASTERSLAVEMODE_DISABLE;
  if (HAL_TIMEx_MasterConfigSynchronization(&htim1, &sMasterConfig) != HAL_OK)
  {
    Error_Handler();
  }
  sConfigOC.OCMode = TIM_OCMODE_PWM1;
  sConfigOC.Pulse = 0;
  sConfigOC.OCPolarity = TIM_OCPOLARITY_HIGH;
  sConfigOC.OCNPolarity = TIM_OCNPOLARITY_HIGH;
  sConfigOC.OCFastMode = TIM_OCFAST_DISABLE;
  sConfigOC.OCIdleState = TIM_OCIDLESTATE_RESET;
  sConfigOC.OCNIdleState = TIM_OCNIDLESTATE_RESET;
  if (HAL_TIM_PWM_ConfigChannel(&htim1, &sConfigOC, TIM_CHANNEL_1) != HAL_OK)
  {
    Error_Handler();
  }
  sBreakDeadTimeConfig.OffStateRunMode = TIM_OSSR_DISABLE;
  sBreakDeadTimeConfig.OffStateIDLEMode = TIM_OSSI_DISABLE;
  sBreakDeadTimeConfig.LockLevel = TIM_LOCKLEVEL_OFF;
  sBreakDeadTimeConfig.DeadTime = 0;
  sBreakDeadTimeConfig.BreakState = TIM_BREAK_DISABLE;
  sBreakDeadTimeConfig.BreakPolarity = TIM_BREAKPOLARITY_HIGH;
  sBreakDeadTimeConfig.AutomaticOutput = TIM_AUTOMATICOUTPUT_DISABLE;
  if (HAL_TIMEx_ConfigBreakDeadTime(&htim1, &sBreakDeadTimeConfig) != HAL_OK)
  {
    Error_Handler();
  }
  HAL_TIM_MspPostInit(&htim1);

}

static void MX_TIM2_Init(void)
{

  TIM_ClockConfigTypeDef sClockSourceConfig = {0};
  TIM_MasterConfigTypeDef sMasterConfig = {0};

  htim2.Instance = TIM2;
  htim2.Init.Prescaler = 7200-1;
  htim2.Init.CounterMode = TIM_COUNTERMODE_UP;
  htim2.Init.Period = 10000-1;
  htim2.Init.ClockDivision = TIM_CLOCKDIVISION_DIV1;
  htim2.Init.AutoReloadPreload = TIM_AUTORELOAD_PRELOAD_DISABLE;
  if (HAL_TIM_Base_Init(&htim2) != HAL_OK)
  {
    Error_Handler();
  }
  sClockSourceConfig.ClockSource = TIM_CLOCKSOURCE_INTERNAL;
  if (HAL_TIM_ConfigClockSource(&htim2, &sClockSourceConfig) != HAL_OK)
  {
    Error_Handler();
  }
  sMasterConfig.MasterOutputTrigger = TIM_TRGO_RESET;
  sMasterConfig.MasterSlaveMode = TIM_MASTERSLAVEMODE_DISABLE;
  if (HAL_TIMEx_MasterConfigSynchronization(&htim2, &sMasterConfig) != HAL_OK)
  {
    Error_Handler();
  }

}

static void MX_DMA_Init(void)
{

  /* DMA controller clock enable */
  __HAL_RCC_DMA1_CLK_ENABLE();

  /* DMA interrupt init */
  /* DMA1_Channel1_IRQn interrupt configuration */
  HAL_NVIC_SetPriority(DMA1_Channel1_IRQn, 0, 0);
  HAL_NVIC_EnableIRQ(DMA1_Channel1_IRQn);

}

static void MX_GPIO_Init(void)
{
  GPIO_InitTypeDef GPIO_InitStruct = {0};

  /* GPIO Ports Clock Enable */
  __HAL_RCC_GPIOC_CLK_ENABLE();
  __HAL_RCC_GPIOD_CLK_ENABLE();
  __HAL_RCC_GPIOA_CLK_ENABLE();
  __HAL_RCC_GPIOB_CLK_ENABLE();

  /*Configure GPIO pin Output Level */
  HAL_GPIO_WritePin(PSON_CTRL_GPIO_Port, PSON_CTRL_Pin, GPIO_PIN_RESET);

  /*Configure GPIO pin Output Level */
  HAL_GPIO_WritePin(LED_FAULT_GPIO_Port, LED_FAULT_Pin, GPIO_PIN_RESET);

  /*Configure GPIO pin Output Level */
  HAL_GPIO_WritePin(LED_RUN_GPIO_Port, LED_RUN_Pin, GPIO_PIN_SET);

  /*Configure GPIO pin : PA9 */
  GPIO_InitStruct.Pin = GPIO_PIN_9;
  GPIO_InitStruct.Mode = GPIO_MODE_IT_RISING_FALLING;
  GPIO_InitStruct.Pull = GPIO_PULLUP;
  HAL_GPIO_Init(GPIOA, &GPIO_InitStruct);

  /*Configure GPIO pin : PSON_CTRL_Pin */
  GPIO_InitStruct.Pin = PSON_CTRL_Pin;
  GPIO_InitStruct.Mode = GPIO_MODE_OUTPUT_PP;
  GPIO_InitStruct.Pull = GPIO_PULLDOWN;
  GPIO_InitStruct.Speed = GPIO_SPEED_FREQ_LOW;
  HAL_GPIO_Init(PSON_CTRL_GPIO_Port, &GPIO_InitStruct);

  /*Configure GPIO pin : PSOK_SIG_Pin */
  GPIO_InitStruct.Pin = PSOK_SIG_Pin;
  GPIO_InitStruct.Mode = GPIO_MODE_INPUT;
  GPIO_InitStruct.Pull = GPIO_NOPULL;
  HAL_GPIO_Init(PSOK_SIG_GPIO_Port, &GPIO_InitStruct);

  /*Configure GPIO pins : LED_FAULT_Pin LED_RUN_Pin */
  GPIO_InitStruct.Pin = LED_FAULT_Pin|LED_RUN_Pin;
  GPIO_InitStruct.Mode = GPIO_MODE_OUTPUT_PP;
  GPIO_InitStruct.Pull = GPIO_NOPULL;
  GPIO_InitStruct.Speed = GPIO_SPEED_FREQ_LOW;
  HAL_GPIO_Init(GPIOB, &GPIO_InitStruct);

  /* EXTI interrupt init*/
  HAL_NVIC_SetPriority(EXTI9_5_IRQn, 0, 0);
  HAL_NVIC_EnableIRQ(EXTI9_5_IRQn);

}

void Error_Handler(void)
{
  __disable_irq();
  while (1)
  {
  }
}
